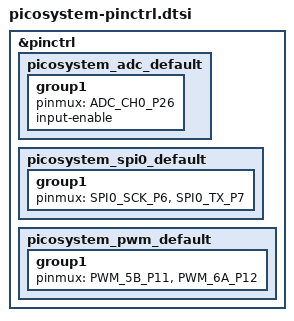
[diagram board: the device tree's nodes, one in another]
/*
 * Copyright (c) 2026 PicoSystem Playground contributors
 *
 * SPDX-License-Identifier: Apache-2.0
 */

#include <zephyr/dt-bindings/pinctrl/rpi-pico-rp2040-pinctrl.h>

&pinctrl {
	picosystem_adc_default: picosystem_adc_default {
		group1 {
			pinmux = <ADC_CH0_P26>;
			input-enable;
		};
	};

	picosystem_spi0_default: picosystem_spi0_default {
		group1 {
			pinmux = <SPI0_SCK_P6>, <SPI0_TX_P7>;
		};
	};

	picosystem_pwm_default: picosystem_pwm_default {
		group1 {
			pinmux = <PWM_5B_P11>, <PWM_6A_P12>;
		};
	};
};
